# STM32L15xxxA register map
File version: 1.0
CPU: 
Registers are 32-bit, read-write, reset 0x0 unless marked. A register's access mark holds for its fields unless they carry their own. Offsets are from the block's base; [hi:lo] are bit positions; {n}, {i} and the like mark numbered series.

## USB — Universal serial bus full-speed device interface
Base 0x40005C00
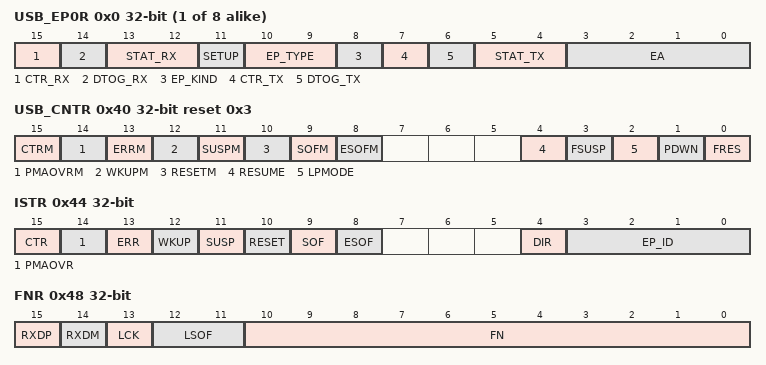
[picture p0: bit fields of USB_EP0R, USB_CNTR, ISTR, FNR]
{0x0+4i} USB_EP{i}R (i=0..7) — endpoint {i} register
  [15] CTR_RX — Correct transfer for reception
  [14] DTOG_RX — Data Toggle, for reception transfers
  [13:12] STAT_RX — Status bits, for reception transfers
  [11] SETUP — Setup transaction completed
  [10:9] EP_TYPE — Endpoint type
  [8] EP_KIND — Endpoint kind
  [7] CTR_TX — Correct Transfer for transmission
  [6] DTOG_TX — Data Toggle, for transmission transfers
  [5:4] STAT_TX — Status bits, for transmission transfers
  [3:0] EA — Endpoint address
0x40 USB_CNTR reset 0x3 — control register
  [15] CTRM — Correct transfer interrupt mask
  [14] PMAOVRM — Packet memory area over / underrun interrupt mask
  [13] ERRM — Error interrupt mask
  [12] WKUPM — Wakeup interrupt mask
  [11] SUSPM — Suspend mode interrupt mask
  [10] RESETM — USB reset interrupt mask
  [9] SOFM — Start of frame interrupt mask
  [8] ESOFM — Expected start of frame interrupt mask
  [4] RESUME — Resume request
  [3] FSUSP — Force suspend
  [2] LPMODE — Low-power mode
  [1] PDWN — Power down
  [0] FRES — Force USB Reset
0x44 ISTR — interrupt status register
  [15] CTR — Correct transfer
  [14] PMAOVR — Packet memory area over / underrun
  [13] ERR — Error
  [12] WKUP — Wakeup
  [11] SUSP — Suspend mode request
  [10] RESET — reset request
  [9] SOF — start of frame
  [8] ESOF — Expected start frame
  [4] DIR — Direction of transaction
  [3:0] EP_ID — Endpoint Identifier
0x48 FNR ro — frame number register
  [15] RXDP — Receive data + line status
  [14] RXDM — Receive data - line status
  [13] LCK — Locked
  [12:11] LSOF — Lost SOF
  [10:0] FN — Frame number
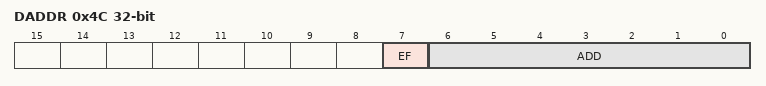
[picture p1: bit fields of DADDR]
0x4C DADDR — device address
  [7] EF — Enable function
  [6:0] ADD — Device address
0x50 BTABLE — Buffer table address
  [15:3] BTABLE — Buffer table

## USB_SRAM — Universal serial bus full-speed device interface
Base 0x40006000
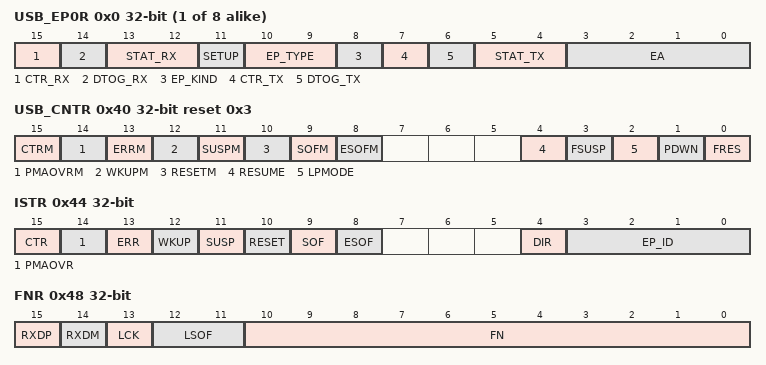
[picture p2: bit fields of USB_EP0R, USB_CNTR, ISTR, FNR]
{0x0+4i} USB_EP{i}R (i=0..7) — endpoint {i} register
  [15] CTR_RX — Correct transfer for reception
  [14] DTOG_RX — Data Toggle, for reception transfers
  [13:12] STAT_RX — Status bits, for reception transfers
  [11] SETUP — Setup transaction completed
  [10:9] EP_TYPE — Endpoint type
  [8] EP_KIND — Endpoint kind
  [7] CTR_TX — Correct Transfer for transmission
  [6] DTOG_TX — Data Toggle, for transmission transfers
  [5:4] STAT_TX — Status bits, for transmission transfers
  [3:0] EA — Endpoint address
0x40 USB_CNTR reset 0x3 — control register
  [15] CTRM — Correct transfer interrupt mask
  [14] PMAOVRM — Packet memory area over / underrun interrupt mask
  [13] ERRM — Error interrupt mask
  [12] WKUPM — Wakeup interrupt mask
  [11] SUSPM — Suspend mode interrupt mask
  [10] RESETM — USB reset interrupt mask
  [9] SOFM — Start of frame interrupt mask
  [8] ESOFM — Expected start of frame interrupt mask
  [4] RESUME — Resume request
  [3] FSUSP — Force suspend
  [2] LPMODE — Low-power mode
  [1] PDWN — Power down
  [0] FRES — Force USB Reset
0x44 ISTR — interrupt status register
  [15] CTR — Correct transfer
  [14] PMAOVR — Packet memory area over / underrun
  [13] ERR — Error
  [12] WKUP — Wakeup
  [11] SUSP — Suspend mode request
  [10] RESET — reset request
  [9] SOF — start of frame
  [8] ESOF — Expected start frame
  [4] DIR — Direction of transaction
  [3:0] EP_ID — Endpoint Identifier
0x48 FNR ro — frame number register
  [15] RXDP — Receive data + line status
  [14] RXDM — Receive data - line status
  [13] LCK — Locked
  [12:11] LSOF — Lost SOF
  [10:0] FN — Frame number
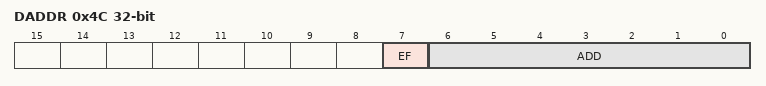
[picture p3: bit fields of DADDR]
0x4C DADDR — device address
  [7] EF — Enable function
  [6:0] ADD — Device address
0x50 BTABLE — Buffer table address
  [15:3] BTABLE — Buffer table

## WWDG — Window watchdog
Base 0x40002C00
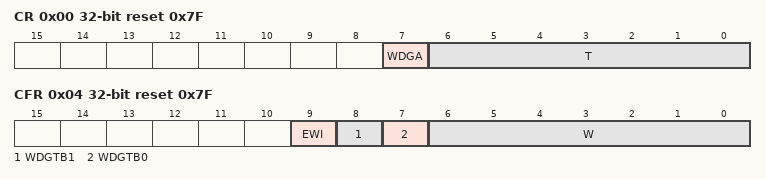
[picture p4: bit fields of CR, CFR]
0x00 CR access per field reset 0x7F — Control register
  [7] WDGA wo — Activation bit
  [6:0] T rw — 7-bit counter (MSB to LSB)
0x04 CFR access per field reset 0x7F — Configuration register
  [9] EWI wo — Early wakeup interrupt
  [8] WDGTB1 rw — Timer base
  [7] WDGTB0 rw
  [6:0] W rw — 7-bit window value
0x08 SR
  [0] EWIF

## NVIC — Nested Vectored Interrupt Controller
Base 0xE000E000
0x04 ICTR ro — Interrupt Controller Type Register
  [3:0] INTLINESNUM — Total number of interrupt lines in groups
0x100 ISER0 — Interrupt Set-Enable Register
  [31:0] SETENA
0x104 ISER1 — Interrupt Set-Enable Register
  [31:0] SETENA
0x180 ICER0 — Interrupt Clear-Enable Register
  [31:0] CLRENA
0x184 ICER1 — Interrupt Clear-Enable Register
  [31:0] CLRENA
0x200 ISPR0 — Interrupt Set-Pending Register
  [31:0] SETPEND
0x204 ISPR1 — Interrupt Set-Pending Register
  [31:0] SETPEND
0x280 ICPR0 — Interrupt Clear-Pending Register
  [31:0] CLRPEND
0x284 ICPR1 — Interrupt Clear-Pending Register
  [31:0] CLRPEND
0x300 IABR0 ro — Interrupt Active Bit Register
  [31:0] ACTIVE
0x304 IABR1 ro — Interrupt Active Bit Register
  [31:0] ACTIVE
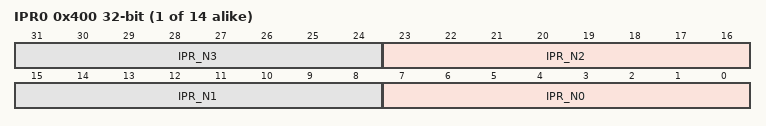
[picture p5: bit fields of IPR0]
{0x400+4i} IPR{i} (i=0..13) — Interrupt Priority Register
  [8n+7:8n] IPR_N{n} (n=0..3)
0xF00 STIR wo — Software Triggered Interrupt Register
  [8:0] INTID — interrupt to be triggered

## DBG — Debug support
Base 0xE0042000
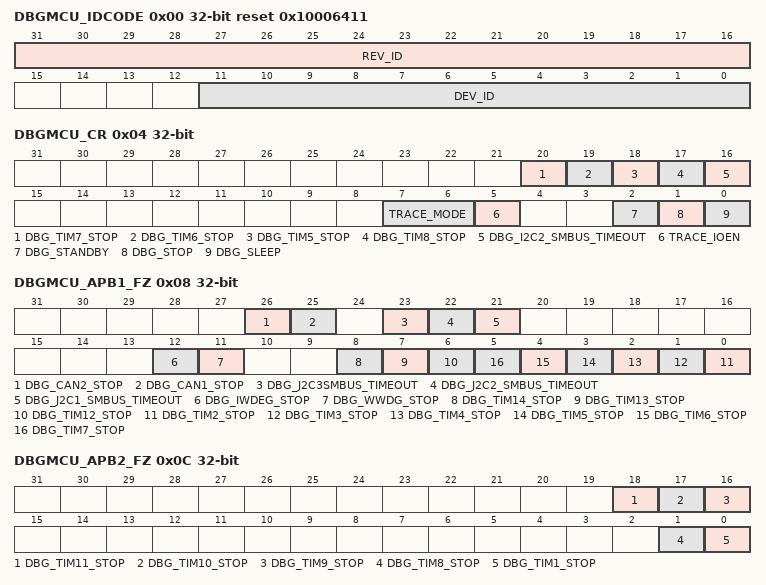
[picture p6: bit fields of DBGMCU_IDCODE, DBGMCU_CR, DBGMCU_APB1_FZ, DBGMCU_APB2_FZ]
0x00 DBGMCU_IDCODE ro reset 0x10006411 — IDCODE
  [31:16] REV_ID, [11:0] DEV_ID
0x04 DBGMCU_CR — Control Register
  [20] DBG_TIM7_STOP, [19] DBG_TIM6_STOP, [18] DBG_TIM5_STOP, [17] DBG_TIM8_STOP, [16] DBG_I2C2_SMBUS_TIMEOUT, [7:6] TRACE_MODE, [5] TRACE_IOEN, [2] DBG_STANDBY, [1] DBG_STOP, [0] DBG_SLEEP
0x08 DBGMCU_APB1_FZ — Debug MCU APB1 Freeze registe
  [26] DBG_CAN2_STOP, [25] DBG_CAN1_STOP, [23] DBG_J2C3SMBUS_TIMEOUT, [22] DBG_J2C2_SMBUS_TIMEOUT, [21] DBG_J2C1_SMBUS_TIMEOUT, [12] DBG_IWDEG_STOP, [11] DBG_WWDG_STOP, [8] DBG_TIM14_STOP, [7] DBG_TIM13_STOP, [6] DBG_TIM12_STOP, [n-2] DBG_TIM{n}_STOP (n=2..7)
0x0C DBGMCU_APB2_FZ — Debug MCU APB2 Freeze registe
  [18] DBG_TIM11_STOP — TIM11 counter stopped when core is halted
  [17] DBG_TIM10_STOP — TIM10 counter stopped when core is halted
  [16] DBG_TIM9_STOP — TIM9 counter stopped when core is halted
  [1] DBG_TIM8_STOP — TIM8 counter stopped when core is halted
  [0] DBG_TIM1_STOP — TIM1 counter stopped when core is halted
